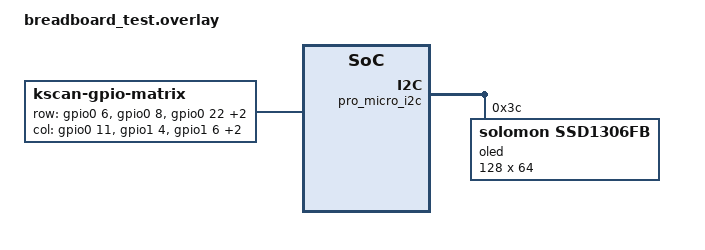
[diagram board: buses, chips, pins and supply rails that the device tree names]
/ {
    chosen {
        zmk,kscan = &kscan0;
        zephyr,display = &oled;
    };

    kscan0: kscan {
        compatible = "zmk,kscan-gpio-matrix";
        label = "KSCAN";
        diode-direction = "col2row";

        row-gpios
            = <&gpio0 6  (GPIO_ACTIVE_HIGH | GPIO_PULL_DOWN)>
            , <&gpio0 8  (GPIO_ACTIVE_HIGH | GPIO_PULL_DOWN)>
            , <&gpio0 22 (GPIO_ACTIVE_HIGH | GPIO_PULL_DOWN)>
            , <&gpio0 24 (GPIO_ACTIVE_HIGH | GPIO_PULL_DOWN)>
            , <&gpio1 0  (GPIO_ACTIVE_HIGH | GPIO_PULL_DOWN)>
            ;

        col-gpios
            = <&gpio0 11 GPIO_ACTIVE_HIGH>
            , <&gpio1 4  GPIO_ACTIVE_HIGH>
            , <&gpio1 6  GPIO_ACTIVE_HIGH>
            , <&gpio0 31 GPIO_ACTIVE_HIGH>
            , <&gpio0 9  GPIO_ACTIVE_HIGH>
            ;
    };
};

&pro_micro_i2c {
    status = "okay";

    oled: ssd1306@3c {
        compatible = "solomon,ssd1306fb";
        reg = <0x3c>;
        width = <128>;
        height = <64>;
        segment-offset = <0>;
        page-offset = <0>;
        display-offset = <0>;
        multiplex-ratio = <63>;
        prechargep = <0x22>;
        segment-remap;
        com-invdir;
    };
};
